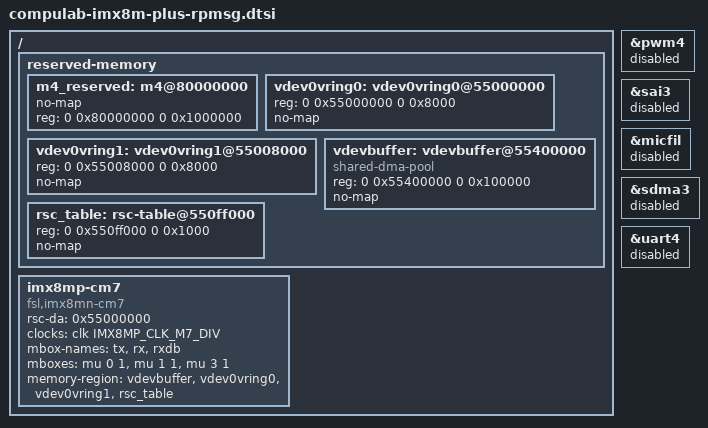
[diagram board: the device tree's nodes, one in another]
/*
 * Copyright 2022 CompuLab
 *
 * This program is free software; you can redistribute it and/or
 * modify it under the terms of the GNU General Public License
 * as published by the Free Software Foundation; either version 2
 * of the License, or (at your option) any later version.
 *
 * This program is distributed in the hope that it will be useful,
 * but WITHOUT ANY WARRANTY; without even the implied warranty of
 * MERCHANTABILITY or FITNESS FOR A PARTICULAR PURPOSE.  See the
 * GNU General Public License for more details.
 */

/ {
	reserved-memory {
		#address-cells = <2>;
		#size-cells = <2>;
		ranges;

		m4_reserved: m4@80000000 {
			no-map;
			reg = <0 0x80000000 0 0x1000000>;
		};

		vdev0vring0: vdev0vring0@55000000 {
			reg = <0 0x55000000 0 0x8000>;
			no-map;
		};

		vdev0vring1: vdev0vring1@55008000 {
			reg = <0 0x55008000 0 0x8000>;
			no-map;
		};

		vdevbuffer: vdevbuffer@55400000 {
			compatible = "shared-dma-pool";
			reg = <0 0x55400000 0 0x100000>;
			no-map;
		};

		rsc_table: rsc-table@550ff000 {
			reg = <0 0x550ff000 0 0x1000>;
			no-map;
		};
	};

	imx8mp-cm7 {
		compatible = "fsl,imx8mn-cm7";
		rsc-da = <0x55000000>;
		clocks = <&clk IMX8MP_CLK_M7_DIV>;
		mbox-names = "tx", "rx", "rxdb";
		mboxes = <&mu 0 1
			  &mu 1 1
			  &mu 3 1>;
		memory-region = <&vdevbuffer>, <&vdev0vring0>, <&vdev0vring1>, <&rsc_table>;
		status = "okay";
	};
};

&pwm4{
	status = "disabled";
};

&sai3 {
	status = "disabled";
};

&micfil {
	status = "disabled";
};

&sdma3{
	status = "disabled";
};

&uart4 {
	status = "disabled";
};
